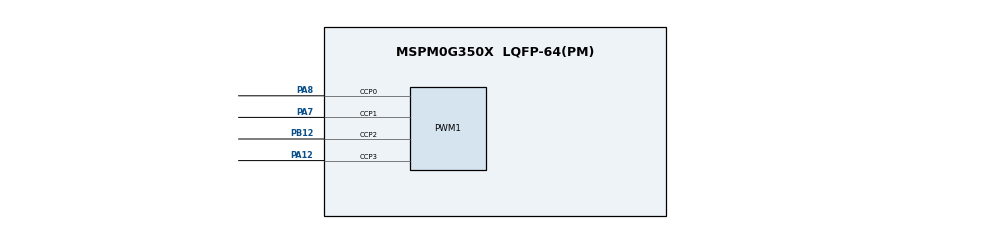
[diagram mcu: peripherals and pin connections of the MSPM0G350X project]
/**
 * @cliArgs --device "MSPM0G350X" --part "Default" --package "LQFP-64(PM)" --product "mspm0_sdk@2.05.01.00"
 * @versions {"tool":"1.24.0+4110"}
 */

/**
 * Import the modules used in this configuration.
 */
const ADC12  = scripting.addModule("/ti/driverlib/ADC12", {}, false);
const ADC121 = ADC12.addInstance();
const GPIO   = scripting.addModule("/ti/driverlib/GPIO", {}, false);
const GPIO1  = GPIO.addInstance();
const PWM    = scripting.addModule("/ti/driverlib/PWM", {}, false);
const PWM1   = PWM.addInstance();
const SYSCTL = scripting.addModule("/ti/driverlib/SYSCTL");
const TIMER  = scripting.addModule("/ti/driverlib/TIMER", {}, false);
const TIMER1 = TIMER.addInstance();
const UART   = scripting.addModule("/ti/driverlib/UART", {}, false);
const UART1  = UART.addInstance();

/**
 * Write custom configuration values to the imported modules.
 */
ADC121.$name               = "ADC12_0";
ADC121.repeatMode          = true;
ADC121.adcMem0chansel      = "DL_ADC12_INPUT_CHAN_2";
ADC121.powerDownMode       = "DL_ADC12_POWER_DOWN_MODE_MANUAL";
ADC121.sampleTime0         = "1us";
ADC121.peripheral.$assign  = "ADC1";
ADC121.adcPin2Config.$name = "ti_driverlib_gpio_GPIOPinGeneric0";

const Board = scripting.addModule("/ti/driverlib/Board", {}, false);

GPIO1.$name                          = "ADDR";
GPIO1.associatedPins.create(3);
GPIO1.associatedPins[0].$name        = "PIN_2";
GPIO1.associatedPins[0].assignedPort = "PORTB";
GPIO1.associatedPins[0].assignedPin  = "17";
GPIO1.associatedPins[1].$name        = "PIN_1";
GPIO1.associatedPins[1].assignedPort = "PORTB";
GPIO1.associatedPins[1].assignedPin  = "19";
GPIO1.associatedPins[2].$name        = "PIN_0";
GPIO1.associatedPins[2].assignedPort = "PORTA";
GPIO1.associatedPins[2].assignedPin  = "22";

PWM1.$name                      = "PWM_0";
PWM1.timerCount                 = 3200;
PWM1.ccIndex                    = [0,1,2,3];
PWM1.PWM_CHANNEL_0.$name        = "ti_driverlib_pwm_PWMTimerCC0";
PWM1.PWM_CHANNEL_1.$name        = "ti_driverlib_pwm_PWMTimerCC1";
PWM1.ccp0PinConfig.$name        = "ti_driverlib_gpio_GPIOPinGeneric3";
PWM1.ccp1PinConfig.$name        = "ti_driverlib_gpio_GPIOPinGeneric4";
PWM1.peripheral.ccp0Pin.$assign = "PA8";
PWM1.peripheral.ccp1Pin.$assign = "PA7";
PWM1.peripheral.ccp2Pin.$assign = "PB12";
PWM1.peripheral.ccp3Pin.$assign = "PA12";
PWM1.PWM_CHANNEL_2.$name        = "ti_driverlib_pwm_PWMTimerCC2";
PWM1.PWM_CHANNEL_3.$name        = "ti_driverlib_pwm_PWMTimerCC3";
PWM1.ccp2PinConfig.$name        = "ti_driverlib_gpio_GPIOPinGeneric5";
PWM1.ccp3PinConfig.$name        = "ti_driverlib_gpio_GPIOPinGeneric6";

SYSCTL.forceDefaultClkConfig = true;

TIMER1.$name            = "TIM_GAP";
TIMER1.timerClkPrescale = 200;
TIMER1.timerMode        = "PERIODIC";
TIMER1.interrupts       = ["ZERO"];
TIMER1.timerPeriod      = "10ms";

UART1.$name             = "UART_0";
UART1.targetBaudRate    = 115200;
UART1.txPinConfig.$name = "ti_driverlib_gpio_GPIOPinGeneric1";
UART1.rxPinConfig.$name = "ti_driverlib_gpio_GPIOPinGeneric2";

/**
 * Pinmux solution for unlocked pins/peripherals. This ensures that minor changes to the automatic solver in a future
 * version of the tool will not impact the pinmux you originally saw.  These lines can be completely deleted in order to
 * re-solve from scratch.
 */
ADC121.peripheral.adcPin2.$suggestSolution   = "PA17";
Board.peripheral.$suggestSolution            = "DEBUGSS";
Board.peripheral.swclkPin.$suggestSolution   = "PA20";
Board.peripheral.swdioPin.$suggestSolution   = "PA19";
GPIO1.associatedPins[0].pin.$suggestSolution = "PB17";
GPIO1.associatedPins[1].pin.$suggestSolution = "PB19";
GPIO1.associatedPins[2].pin.$suggestSolution = "PA22";
PWM1.peripheral.$suggestSolution             = "TIMA0";
SYSCTL.peripheral.$suggestSolution           = "SYSCTL";
TIMER1.peripheral.$suggestSolution           = "TIMA1";
UART1.peripheral.$suggestSolution            = "UART0";
UART1.peripheral.rxPin.$suggestSolution      = "PA1";
UART1.peripheral.txPin.$suggestSolution      = "PA0";
